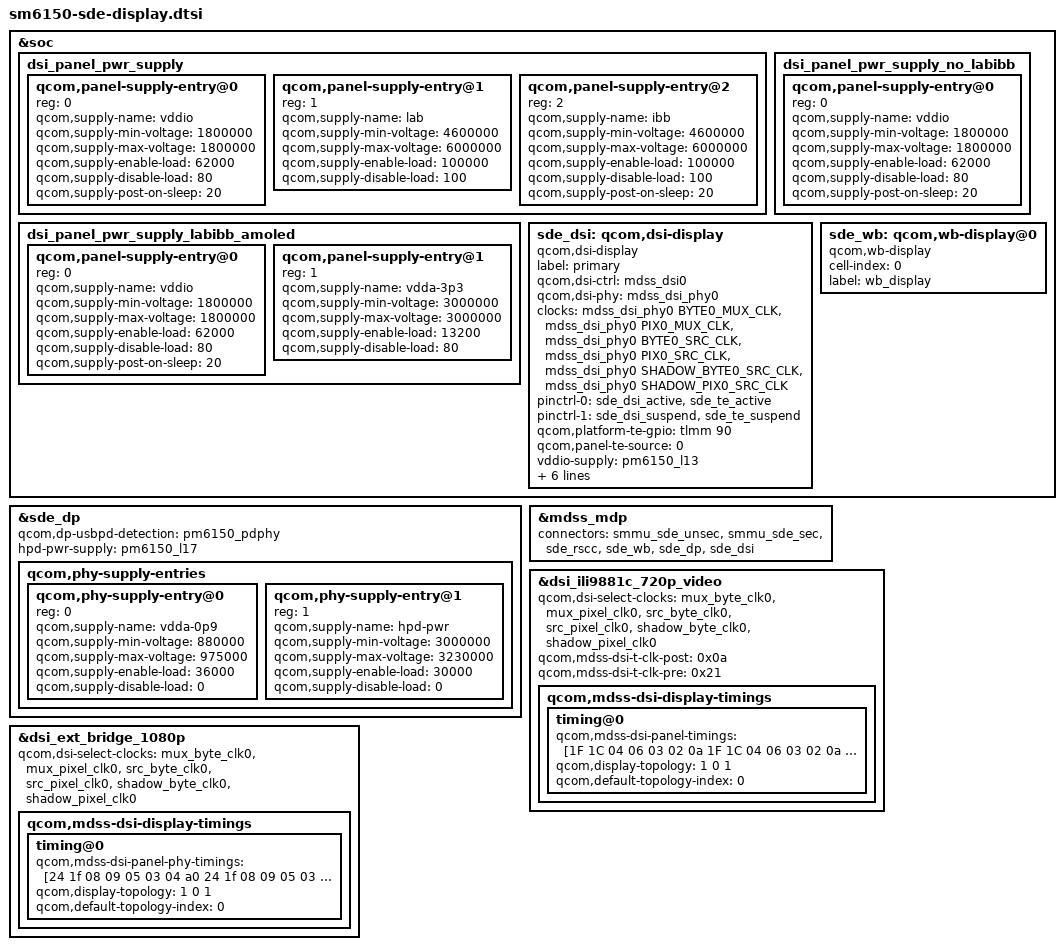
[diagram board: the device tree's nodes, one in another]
#include <dt-bindings/clock/mdss-14nm-pll-clk.h>
#include "dsi-panel-ili988c-dual-video.dtsi"
#include "dsi-panel-ext-bridge-1080p.dtsi"

&soc {
	dsi_panel_pwr_supply: dsi_panel_pwr_supply {
		#address-cells = <1>;
		#size-cells = <0>;

		qcom,panel-supply-entry@0 {
			reg = <0>;
			qcom,supply-name = "vddio";
			qcom,supply-min-voltage = <1800000>;
			qcom,supply-max-voltage = <1800000>;
			qcom,supply-enable-load = <62000>;
			qcom,supply-disable-load = <80>;
			qcom,supply-post-on-sleep = <20>;
		};

		qcom,panel-supply-entry@1 {
			reg = <1>;
			qcom,supply-name = "lab";
			qcom,supply-min-voltage = <4600000>;
			qcom,supply-max-voltage = <6000000>;
			qcom,supply-enable-load = <100000>;
			qcom,supply-disable-load = <100>;
		};

		qcom,panel-supply-entry@2 {
			reg = <2>;
			qcom,supply-name = "ibb";
			qcom,supply-min-voltage = <4600000>;
			qcom,supply-max-voltage = <6000000>;
			qcom,supply-enable-load = <100000>;
			qcom,supply-disable-load = <100>;
			qcom,supply-post-on-sleep = <20>;
		};
	};

	dsi_panel_pwr_supply_no_labibb: dsi_panel_pwr_supply_no_labibb {
		#address-cells = <1>;
		#size-cells = <0>;

		qcom,panel-supply-entry@0 {
			reg = <0>;
			qcom,supply-name = "vddio";
			qcom,supply-min-voltage = <1800000>;
			qcom,supply-max-voltage = <1800000>;
			qcom,supply-enable-load = <62000>;
			qcom,supply-disable-load = <80>;
			qcom,supply-post-on-sleep = <20>;
		};
	};

	dsi_panel_pwr_supply_labibb_amoled: dsi_panel_pwr_supply_labibb_amoled {
		#address-cells = <1>;
		#size-cells = <0>;

		qcom,panel-supply-entry@0 {
			reg = <0>;
			qcom,supply-name = "vddio";
			qcom,supply-min-voltage = <1800000>;
			qcom,supply-max-voltage = <1800000>;
			qcom,supply-enable-load = <62000>;
			qcom,supply-disable-load = <80>;
			qcom,supply-post-on-sleep = <20>;
		};

		qcom,panel-supply-entry@1 {
			reg = <1>;
			qcom,supply-name = "vdda-3p3";
			qcom,supply-min-voltage = <3000000>;
			qcom,supply-max-voltage = <3000000>;
			qcom,supply-enable-load = <13200>;
			qcom,supply-disable-load = <80>;
		};
	};

	sde_dsi: qcom,dsi-display {
		compatible = "qcom,dsi-display";
		label = "primary";

		qcom,dsi-ctrl = <&mdss_dsi0>;
		qcom,dsi-phy = <&mdss_dsi_phy0>;

		clocks = <&mdss_dsi_phy0 BYTE0_MUX_CLK>,
			 <&mdss_dsi_phy0 PIX0_MUX_CLK>,
			 <&mdss_dsi_phy0 BYTE0_SRC_CLK>,
			 <&mdss_dsi_phy0 PIX0_SRC_CLK>,
			 <&mdss_dsi_phy0 SHADOW_BYTE0_SRC_CLK>,
			 <&mdss_dsi_phy0 SHADOW_PIX0_SRC_CLK>;
		clock-names = "mux_byte_clk0", "mux_pixel_clk0",
			"src_byte_clk0", "src_pixel_clk0",
			"shadow_byte_clk0", "shadow_pixel_clk0";
		pinctrl-names = "panel_active", "panel_suspend";
		pinctrl-0 = <&sde_dsi_active &sde_te_active>;
		pinctrl-1 = <&sde_dsi_suspend &sde_te_suspend>;

		qcom,platform-te-gpio = <&tlmm 90 0>;
		qcom,panel-te-source = <0>;

		vddio-supply = <&pm6150_l13>;
		vdda-3p3-supply = <&pm6150_l18>;
		lab-supply = <&lcdb_ldo_vreg>;
		ibb-supply = <&lcdb_ncp_vreg>;

		qcom,dsi-default-panel = <&dsi_ili9881c_720p_video>;
		qcom,mdp = <&mdss_mdp>;
	};

	sde_wb: qcom,wb-display@0 {
		compatible = "qcom,wb-display";
		cell-index = <0>;
		label = "wb_display";
	};
};

&sde_dp {
	qcom,dp-usbpd-detection = <&pm6150_pdphy>;
	hpd-pwr-supply = <&pm6150_l17>;
	qcom,phy-supply-entries {
		#address-cells = <1>;
		#size-cells = <0>;
		qcom,phy-supply-entry@0 {
			reg = <0>;
			qcom,supply-name = "vdda-0p9";
			qcom,supply-min-voltage = <880000>;
			qcom,supply-max-voltage = <975000>;
			qcom,supply-enable-load = <36000>;
			qcom,supply-disable-load = <0>;
		};
		qcom,phy-supply-entry@1 {
			reg = <1>;
			qcom,supply-name = "hpd-pwr";
			qcom,supply-min-voltage = <3000000>;
			qcom,supply-max-voltage = <3230000>;
			qcom,supply-enable-load = <30000>;
			qcom,supply-disable-load = <0>;
		};
	};
};

&mdss_mdp {
	connectors = <&smmu_sde_unsec &smmu_sde_sec &sde_rscc &sde_wb &sde_dp &sde_dsi>;
};

&dsi_ili9881c_720p_video {
	qcom,dsi-select-clocks = "mux_byte_clk0", "mux_pixel_clk0",
			"src_byte_clk0", "src_pixel_clk0",
			"shadow_byte_clk0", "shadow_pixel_clk0";
	qcom,mdss-dsi-t-clk-post = <0x0a>;
	qcom,mdss-dsi-t-clk-pre = <0x21>;
	qcom,mdss-dsi-display-timings {
		timing@0 {
			qcom,mdss-dsi-panel-timings =
				[1F 1C 04 06 03 02 0a
				1F 1C 04 06 03 02 0a
				1F 1C 04 06 03 02 0a
				1F 1C 04 06 03 02 0a
				1F 10 04 06 03 02 0a];

			qcom,display-topology = <1 0 1>;
			qcom,default-topology-index = <0>;
		};
	};
};

&dsi_ext_bridge_1080p {
	qcom,dsi-select-clocks = "mux_byte_clk0", "mux_pixel_clk0",
			"src_byte_clk0", "src_pixel_clk0",
			"shadow_byte_clk0", "shadow_pixel_clk0";
	qcom,mdss-dsi-display-timings {
		timing@0{
			qcom,mdss-dsi-panel-phy-timings =
				[24 1f 08 09 05 03 04 a0
				24 1f 08 09 05 03 04 a0
				24 1f 08 09 05 03 04 a0
				24 1f 08 09 05 03 04 a0
				24 1b 08 09 05 03 04 a0];

			qcom,display-topology = <1 0 1>;
			qcom,default-topology-index = <0>;
		};
	};
};
